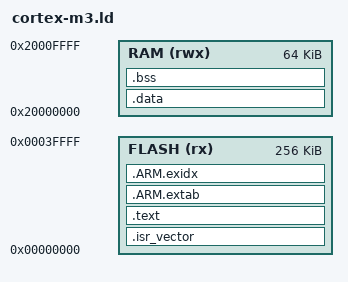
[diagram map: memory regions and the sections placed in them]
ENTRY(Reset_Handler)

MEMORY {
    FLASH (rx) : ORIGIN = 0x00000000, LENGTH = 256K
    RAM (rwx)  : ORIGIN = 0x20000000, LENGTH = 64K
}

SECTIONS {
    .isr_vector : {
        . = ALIGN(4);
        KEEP(*(.isr_vector))
        . = ALIGN(4);
    } > FLASH

    .text : {
        . = ALIGN(4);
        *(.text*)
        *(.rodata*)
        . = ALIGN(4);
    } > FLASH

    /* ARM exception handling sections */
    .ARM.extab : {
        *(.ARM.extab* .gnu.linkonce.armextab.*)
    } > FLASH

    .ARM.exidx : {
        __exidx_start = .;
        *(.ARM.exidx* .gnu.linkonce.armexidx.*)
        __exidx_end = .;
    } > FLASH

    /* Symbol for end of code + rodata = start of initialized data in FLASH */
    _sidata = .;

    .data : AT(_sidata) {
        . = ALIGN(4);
        _sdata = .;
        *(.data*)
        . = ALIGN(4);
        _edata = .;
    } > RAM

    .bss : {
        . = ALIGN(4);
        _sbss = .;
        *(.bss*)
        *(COMMON)
        . = ALIGN(4);
        _ebss = .;
    } > RAM

    /* Define end symbol for heap */
    end = .;
    _end = .;

    /* Remove debug information and other unnecessary sections */
    /DISCARD/ : {
        *(.note.GNU-stack)
        *(.gnu_debuglink)
        *(.gnu.lto_*)
    }
}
